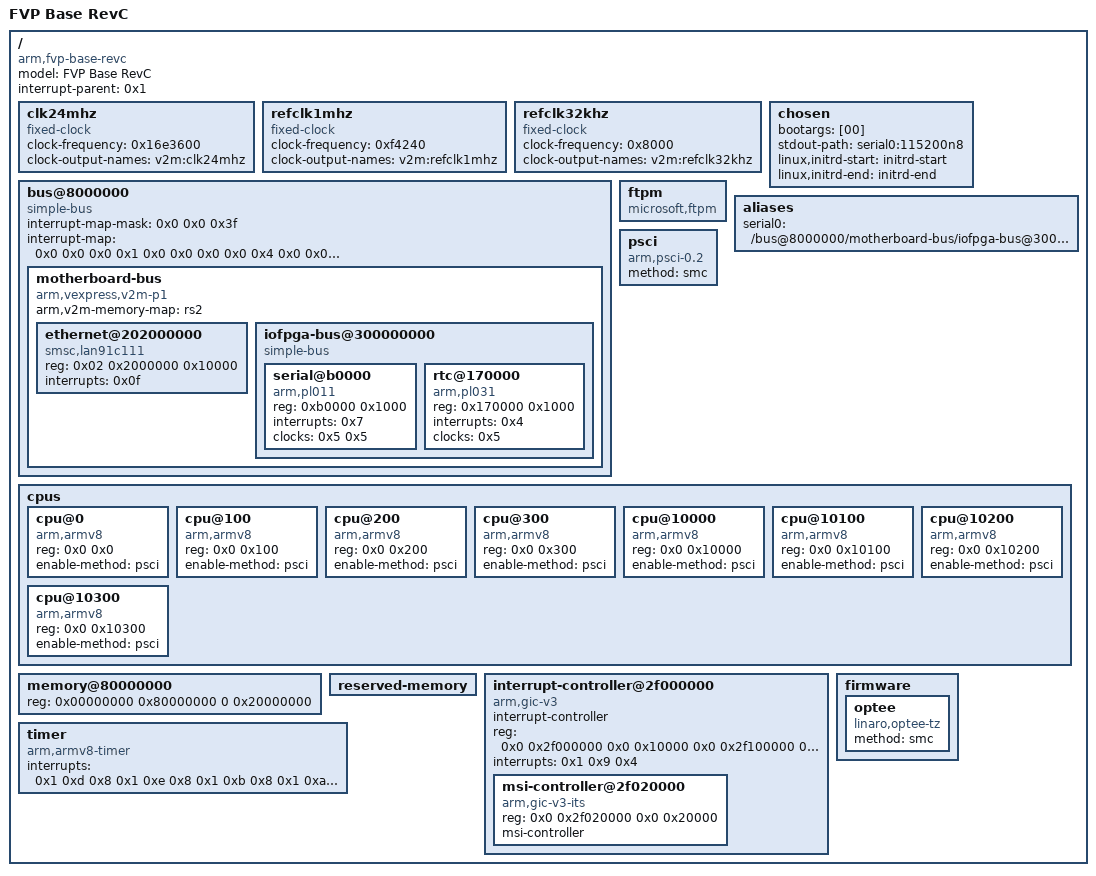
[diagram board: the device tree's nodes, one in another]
/dts-v1/;

/memreserve/	0x0000000080000000 0x0000000000010000;
/ {
	model = "FVP Base RevC";
	compatible = "arm,fvp-base-revc", "arm,vexpress";
	interrupt-parent = <0x1>;
	#address-cells = <0x2>;
	#size-cells = <0x2>;

	clk24mhz {
		compatible = "fixed-clock";
		#clock-cells = <0x0>;
		clock-frequency = <0x16e3600>;
		clock-output-names = "v2m:clk24mhz";
		phandle = <0x5>;
	};

	refclk1mhz {
		compatible = "fixed-clock";
		#clock-cells = <0x0>;
		clock-frequency = <0xf4240>;
		clock-output-names = "v2m:refclk1mhz";
		phandle = <0x4>;
	};

	refclk32khz {
		compatible = "fixed-clock";
		#clock-cells = <0x0>;
		clock-frequency = <0x8000>;
		clock-output-names = "v2m:refclk32khz";
		phandle = <0x3>;
	};
	
	bus@8000000 {
		compatible = "simple-bus";
		#address-cells = <0x2>;
		#size-cells = <0x1>;
		ranges = <0x0 0x0 0x0 0x8000000 0x4000000 0x1 0x0 0x0 0x14000000 0x4000000 0x2 0x0 0x0 0x18000000 0x4000000 0x3 0x0 0x0 0x1c000000 0x4000000 0x4 0x0 0x0 0xc000000 0x4000000 0x5 0x0 0x0 0x10000000 0x4000000>;
		#interrupt-cells = <0x1>;
		interrupt-map-mask = <0x0 0x0 0x3f>;
		interrupt-map = <0x0 0x0 0x0 0x1 0x0 0x0 0x0 0x0 0x4 0x0 0x0 0x1 0x1 0x0 0x0 0x0 0x1 0x4 0x0 0x0 0x2 0x1 0x0 0x0 0x0 0x2 0x4 0x0 0x0 0x3 0x1 0x0 0x0 0x0 0x3 0x4 0x0 0x0 0x4 0x1 0x0 0x0 0x0 0x4 0x4 0x0 0x0 0x5 0x1 0x0 0x0 0x0 0x5 0x4 0x0 0x0 0x6 0x1 0x0 0x0 0x0 0x6 0x4 0x0 0x0 0x7 0x1 0x0 0x0 0x0 0x7 0x4 0x0 0x0 0x8 0x1 0x0 0x0 0x0 0x8 0x4 0x0 0x0 0x9 0x1 0x0 0x0 0x0 0x9 0x4 0x0 0x0 0xa 0x1 0x0 0x0 0x0 0xa 0x4 0x0 0x0 0xb 0x1 0x0 0x0 0x0 0xb 0x4 0x0 0x0 0xc 0x1 0x0 0x0 0x0 0xc 0x4 0x0 0x0 0xd 0x1 0x0 0x0 0x0 0xd 0x4 0x0 0x0 0xe 0x1 0x0 0x0 0x0 0xe 0x4 0x0 0x0 0xf 0x1 0x0 0x0 0x0 0xf 0x4 0x0 0x0 0x10 0x1 0x0 0x0 0x0 0x10 0x4 0x0 0x0 0x11 0x1 0x0 0x0 0x0 0x11 0x4 0x0 0x0 0x12 0x1 0x0 0x0 0x0 0x12 0x4 0x0 0x0 0x13 0x1 0x0 0x0 0x0 0x13 0x4 0x0 0x0 0x14 0x1 0x0 0x0 0x0 0x14 0x4 0x0 0x0 0x15 0x1 0x0 0x0 0x0 0x15 0x4 0x0 0x0 0x16 0x1 0x0 0x0 0x0 0x16 0x4 0x0 0x0 0x17 0x1 0x0 0x0 0x0 0x17 0x4 0x0 0x0 0x18 0x1 0x0 0x0 0x0 0x18 0x4 0x0 0x0 0x19 0x1 0x0 0x0 0x0 0x19 0x4 0x0 0x0 0x1a 0x1 0x0 0x0 0x0 0x1a 0x4 0x0 0x0 0x1b 0x1 0x0 0x0 0x0 0x1b 0x4 0x0 0x0 0x1c 0x1 0x0 0x0 0x0 0x1c 0x4 0x0 0x0 0x1d 0x1 0x0 0x0 0x0 0x1d 0x4 0x0 0x0 0x1e 0x1 0x0 0x0 0x0 0x1e 0x4 0x0 0x0 0x1f 0x1 0x0 0x0 0x0 0x1f 0x4 0x0 0x0 0x20 0x1 0x0 0x0 0x0 0x20 0x4 0x0 0x0 0x21 0x1 0x0 0x0 0x0 0x21 0x4 0x0 0x0 0x22 0x1 0x0 0x0 0x0 0x22 0x4 0x0 0x0 0x23 0x1 0x0 0x0 0x0 0x23 0x4 0x0 0x0 0x24 0x1 0x0 0x0 0x0 0x24 0x4 0x0 0x0 0x25 0x1 0x0 0x0 0x0 0x25 0x4 0x0 0x0 0x26 0x1 0x0 0x0 0x0 0x26 0x4 0x0 0x0 0x27 0x1 0x0 0x0 0x0 0x27 0x4 0x0 0x0 0x28 0x1 0x0 0x0 0x0 0x28 0x4 0x0 0x0 0x29 0x1 0x0 0x0 0x0 0x29 0x4 0x0 0x0 0x2a 0x1 0x0 0x0 0x0 0x2a 0x4 0x0 0x0 0x2b 0x1 0x0 0x0 0x0 0x2b 0x4 0x0 0x0 0x2c 0x1 0x0 0x0 0x0 0x2c 0x4>;

		motherboard-bus {
			arm,v2m-memory-map = "rs2";
			compatible = "arm,vexpress,v2m-p1", "simple-bus";
			#address-cells = <0x2>;
			#size-cells = <0x1>;
			#interrupt-cells = <0x1>;
			ranges;

			ethernet@202000000 {
				compatible = "smsc,lan91c111";
				reg = <0x02 0x2000000 0x10000>;
				interrupts = <0x0f>;
			};

			iofpga-bus@300000000 {
				compatible = "simple-bus";
				#address-cells = <0x1>;
				#size-cells = <0x1>;
				ranges = <0x0 0x3 0x0 0x200000>;


				serial@b0000 {
					compatible = "arm,pl011", "arm,primecell";
					reg = <0xb0000 0x1000>;
					interrupts = <0x7>;
					clocks = <0x5 0x5>;
					clock-names = "uartclk", "apb_pclk";
				};

				rtc@170000 {
					compatible = "arm,pl031", "arm,primecell";
					reg = <0x170000 0x1000>;
					interrupts = <0x4>;
					clocks = <0x5>;
					clock-names = "apb_pclk";
				};
			};
		};
	};

	chosen {
		bootargs = [00];
		stdout-path = "serial0:115200n8";
		linux,initrd-start = <initrd-start>;
		linux,initrd-end = <initrd-end>;
	};

	ftpm {
		compatible = "microsoft,ftpm";
	};

	aliases {
		serial0 = "/bus@8000000/motherboard-bus/iofpga-bus@300000000/serial@b0000";
	};

	psci {
		compatible = "arm,psci-0.2";
		method = "smc";
	};

	cpus {
		#address-cells = <0x2>;
		#size-cells = <0x0>;

		cpu@0 {
			device_type = "cpu";
			compatible = "arm,armv8";
			reg = <0x0 0x0>;
			enable-method = "psci";
		};

		cpu@100 {
			device_type = "cpu";
			compatible = "arm,armv8";
			reg = <0x0 0x100>;
			enable-method = "psci";
		};

		cpu@200 {
			device_type = "cpu";
			compatible = "arm,armv8";
			reg = <0x0 0x200>;
			enable-method = "psci";
		};

		cpu@300 {
			device_type = "cpu";
			compatible = "arm,armv8";
			reg = <0x0 0x300>;
			enable-method = "psci";
		};

		cpu@10000 {
			device_type = "cpu";
			compatible = "arm,armv8";
			reg = <0x0 0x10000>;
			enable-method = "psci";
		};

		cpu@10100 {
			device_type = "cpu";
			compatible = "arm,armv8";
			reg = <0x0 0x10100>;
			enable-method = "psci";
		};

		cpu@10200 {
			device_type = "cpu";
			compatible = "arm,armv8";
			reg = <0x0 0x10200>;
			enable-method = "psci";
		};

		cpu@10300 {
			device_type = "cpu";
			compatible = "arm,armv8";
			reg = <0x0 0x10300>;
			enable-method = "psci";
		};
	};

	memory@80000000 {
		device_type = "memory";
		reg = <0x00000000 0x80000000 0 0x20000000>;
	};

	reserved-memory {
		#address-cells = <0x2>;
		#size-cells = <0x2>;
		ranges;
	};

	interrupt-controller@2f000000 {
		compatible = "arm,gic-v3";
		#interrupt-cells = <0x3>;
		#address-cells = <0x2>;
		#size-cells = <0x2>;
		ranges;
		interrupt-controller;
		reg = <0x0 0x2f000000 0x0 0x10000 0x0 0x2f100000 0x0 0x200000 0x0 0x2c000000 0x0 0x2000 0x0 0x2c010000 0x0 0x2000 0x0 0x2c02f000 0x0 0x2000>;
		interrupts = <0x1 0x9 0x4>;
		phandle = <0x1>;

		msi-controller@2f020000 {
			#msi-cells = <0x1>;
			compatible = "arm,gic-v3-its";
			reg = <0x0 0x2f020000 0x0 0x20000>;
			msi-controller;
			phandle = <0xb>;
		};
	};

	timer {
		compatible = "arm,armv8-timer";
		interrupts = <0x1 0xd 0x8 0x1 0xe 0x8 0x1 0xb 0x8 0x1 0xa 0x8>;
	};

	firmware {

		optee {
	 		compatible = "linaro,optee-tz";
	 		method = "smc";
	 	};
	};
};
